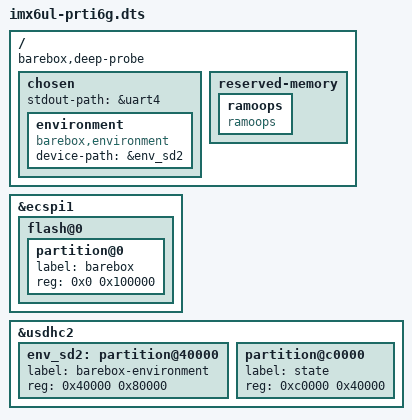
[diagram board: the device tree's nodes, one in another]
// SPDX-License-Identifier: GPL-2.0-or-later
/dts-v1/;

#include <arm/nxp/imx/imx6ul-prti6g.dts>

/ {
	barebox,deep-probe;

	chosen {
		stdout-path = &uart4;

		environment {
			compatible = "barebox,environment";
			device-path = &env_sd2;
		};
	};

	reserved-memory {
		#address-cells = <1>;
		#size-cells = <1>;
		ranges;

		/* Address will be determined by the bootloader */
		ramoops {
			compatible = "ramoops";
		};
	};
};

&ecspi1 {
	flash@0 {
		#address-cells = <1>;
		#size-cells = <1>;

		partition@0 {
			label = "barebox";
			reg = <0x0 0x100000>;
		};
	};
};

&usdhc2 {
	#address-cells = <1>;
	#size-cells = <1>;

	env_sd2: partition@40000 {
		label = "barebox-environment";
		reg = <0x40000 0x80000>;
	};

	partition@c0000 {
		label = "state";
		reg = <0xc0000 0x40000>;
	};
};
